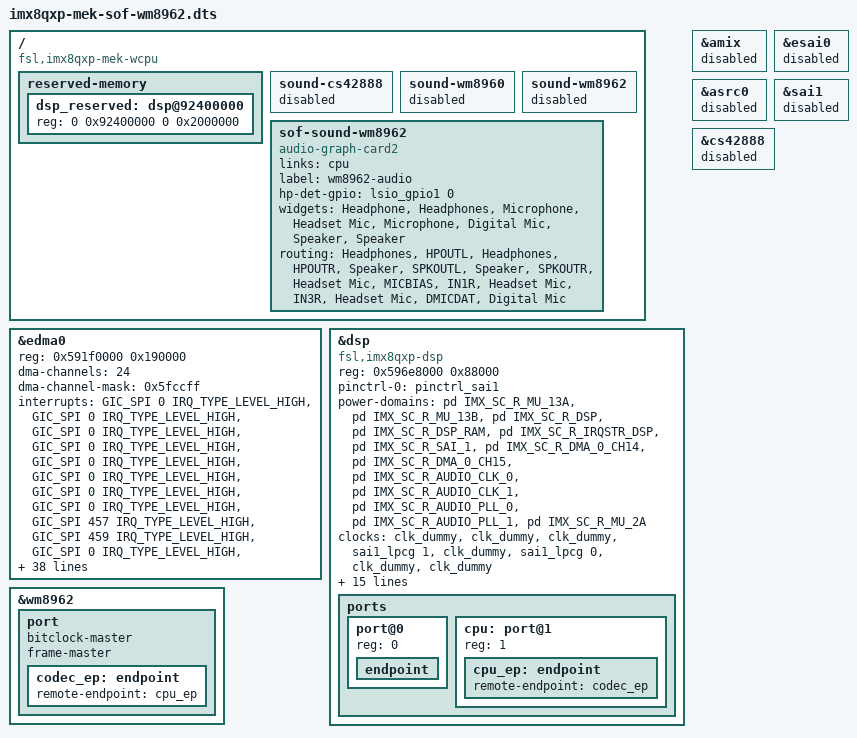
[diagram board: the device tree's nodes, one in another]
// SPDX-License-Identifier: GPL-2.0+
/*
 * Copyright 2023 NXP
 */

#include "imx8qxp-mek-rpmsg.dts"

/delete-node/ &dsp_reserved_heap;
/delete-node/ &dsp_vdev0vring0;
/delete-node/ &dsp_vdev0vring1;
/delete-node/ &dsp_vdev0buffer;

/ {
	compatible = "fsl,imx8qxp-mek-wcpu";

	/delete-node/ sound-wm8960;
	/delete-node/ sound-wm8962;

	reserved-memory {
		dsp_reserved: dsp@92400000 {
			reg = <0 0x92400000 0 0x2000000>;
		};
	};

	sound-cs42888 {
		status = "disabled";
	};

	sound-wm8960 {
		status = "disabled";
	};

	sound-wm8962 {
		status = "disabled";
	};

	sof-sound-wm8962 {
		compatible = "audio-graph-card2";
		links = <&cpu>;
		label = "wm8962-audio";
		hp-det-gpio = <&lsio_gpio1 0 0>;
		widgets =
			"Headphone", "Headphones",
			"Microphone", "Headset Mic",
			"Microphone", "Digital Mic",
			"Speaker", "Speaker";
		routing =
			"Headphones", "HPOUTL",
			"Headphones", "HPOUTR",
			"Speaker", "SPKOUTL",
			"Speaker", "SPKOUTR",
			"Headset Mic", "MICBIAS",
			"IN1R", "Headset Mic",
			"IN3R", "Headset Mic",
			"DMICDAT", "Digital Mic";
	};
};

&edma0 {
	reg = <0x591f0000 0x190000>;
	dma-channels = <24>;
	dma-channel-mask = <0x5fccff>;
	interrupts = <GIC_SPI 0   IRQ_TYPE_LEVEL_HIGH>, /* 0 asrc 0 */
		     <GIC_SPI 0   IRQ_TYPE_LEVEL_HIGH>, /* 1 */
		     <GIC_SPI 0   IRQ_TYPE_LEVEL_HIGH>, /* 2 */
		     <GIC_SPI 0   IRQ_TYPE_LEVEL_HIGH>, /* 3 */
		     <GIC_SPI 0   IRQ_TYPE_LEVEL_HIGH>, /* 4 */
		     <GIC_SPI 0   IRQ_TYPE_LEVEL_HIGH>, /* 5 */
		     <GIC_SPI 0   IRQ_TYPE_LEVEL_HIGH>, /* 6 esai0 */
		     <GIC_SPI 0   IRQ_TYPE_LEVEL_HIGH>, /* 7 */
		     <GIC_SPI 457 IRQ_TYPE_LEVEL_HIGH>, /* 8 spdif0 */
		     <GIC_SPI 459 IRQ_TYPE_LEVEL_HIGH>, /* 9 */
		     <GIC_SPI 0   IRQ_TYPE_LEVEL_HIGH>, /* 10 unused */
		     <GIC_SPI 0   IRQ_TYPE_LEVEL_HIGH>, /* 11 unused */
		     <GIC_SPI 315 IRQ_TYPE_LEVEL_HIGH>, /* 12 sai0 */
		     <GIC_SPI 315 IRQ_TYPE_LEVEL_HIGH>, /* 13 */
		     <GIC_SPI 0   IRQ_TYPE_LEVEL_HIGH>, /* 14 sai1 */
		     <GIC_SPI 0   IRQ_TYPE_LEVEL_HIGH>, /* 15 */
		     <GIC_SPI 0   IRQ_TYPE_LEVEL_HIGH>, /* 16 sai2 */
		     <GIC_SPI 0   IRQ_TYPE_LEVEL_HIGH>, /* 17 sai3 */
		     <GIC_SPI 0   IRQ_TYPE_LEVEL_HIGH>, /* 18 unused */
		     <GIC_SPI 0   IRQ_TYPE_LEVEL_HIGH>, /* 19 unused */
		     <GIC_SPI 0   IRQ_TYPE_LEVEL_HIGH>, /* 20 unused */
		     <GIC_SPI 391 IRQ_TYPE_LEVEL_HIGH>, /* 21 */
		     <GIC_SPI 0   IRQ_TYPE_LEVEL_HIGH>, /* 22 unused */
		     <GIC_SPI 393 IRQ_TYPE_LEVEL_HIGH>, /* 23 */
		     <GIC_SPI 369 IRQ_TYPE_LEVEL_HIGH>;
	power-domains = <&pd IMX_SC_R_DMA_0_CH0>,
			<&pd IMX_SC_R_DMA_0_CH1>,
			<&pd IMX_SC_R_DMA_0_CH2>,
			<&pd IMX_SC_R_DMA_0_CH3>,
			<&pd IMX_SC_R_DMA_0_CH4>,
			<&pd IMX_SC_R_DMA_0_CH5>,
			<&pd IMX_SC_R_DMA_0_CH6>,
			<&pd IMX_SC_R_DMA_0_CH7>,
			<&pd IMX_SC_R_DMA_0_CH8>,
			<&pd IMX_SC_R_DMA_0_CH9>,
			<&pd IMX_SC_R_DMA_0_CH10>,
			<&pd IMX_SC_R_DMA_0_CH11>,
			<&pd IMX_SC_R_DMA_0_CH12>,
			<&pd IMX_SC_R_DMA_0_CH13>,
			<&pd IMX_SC_R_DMA_0_CH14>,
			<&pd IMX_SC_R_DMA_0_CH15>,
			<&pd IMX_SC_R_DMA_0_CH16>,
			<&pd IMX_SC_R_DMA_0_CH17>,
			<&pd IMX_SC_R_DMA_0_CH18>,
			<&pd IMX_SC_R_DMA_0_CH19>,
			<&pd IMX_SC_R_DMA_0_CH20>,
			<&pd IMX_SC_R_DMA_0_CH21>,
			<&pd IMX_SC_R_DMA_0_CH22>,
			<&pd IMX_SC_R_DMA_0_CH23>;
};

&dsp {
	compatible = "fsl,imx8qxp-dsp";
	reg = <0x596e8000 0x88000>;

	pinctrl-names = "default";
	pinctrl-0 = <&pinctrl_sai1>;

	power-domains = <&pd IMX_SC_R_MU_13A>,
		<&pd IMX_SC_R_MU_13B>,
		<&pd IMX_SC_R_DSP>,
		<&pd IMX_SC_R_DSP_RAM>,
		<&pd IMX_SC_R_IRQSTR_DSP>,
		<&pd IMX_SC_R_SAI_1>,
		<&pd IMX_SC_R_DMA_0_CH14>,
		<&pd IMX_SC_R_DMA_0_CH15>,
		<&pd IMX_SC_R_AUDIO_CLK_0>,
		<&pd IMX_SC_R_AUDIO_CLK_1>,
		<&pd IMX_SC_R_AUDIO_PLL_0>,
		<&pd IMX_SC_R_AUDIO_PLL_1>,
		<&pd IMX_SC_R_MU_2A>;

	clock-names = "ipg", "ocram", "core",
		"sai1_bus", "sai1_mclk0", "sai1_mclk1", "sai1_mclk2", "sai1_mclk3";
	clocks = <&clk_dummy>, <&clk_dummy>, <&clk_dummy>,
		<&sai1_lpcg 1>, <&clk_dummy>, <&sai1_lpcg 0>,
		<&clk_dummy>, <&clk_dummy>;
	assigned-clocks = <&acm IMX_ADMA_ACM_SAI1_MCLK_SEL>,
			<&clk IMX_SC_R_AUDIO_PLL_0 IMX_SC_PM_CLK_PLL>,
			<&clk IMX_SC_R_AUDIO_PLL_0 IMX_SC_PM_CLK_MISC0>,
			<&clk IMX_SC_R_AUDIO_PLL_0 IMX_SC_PM_CLK_MISC1>,
			<&sai1_lpcg 0>; /* FIXME: should be sai1, original code is 0 */
	assigned-clock-parents = <&aud_pll_div0_lpcg 0>;
	assigned-clock-rates = <0>, <786432000>, <49152000>, <12288000>, <49152000>;

	mbox-names = "txdb0", "txdb1", "rxdb0", "rxdb1";
	mboxes = <&lsio_mu13 2 0>,
		<&lsio_mu13 2 1>,
		<&lsio_mu13 3 0>,
		<&lsio_mu13 3 1>;
	memory-region = <&dsp_reserved>;
	/delete-property/ firmware-name;

	tplg-name = "sof-imx8-wm8962.tplg";
	machine-drv-name = "asoc-audio-graph-card2";
	status = "okay";

	ports {
		#address-cells = <1>;
		#size-cells = <0>;

		port@0 { reg = <0>; endpoint { /* not used */ }; };
		cpu: port@1 { reg = <1>; cpu_ep: endpoint { remote-endpoint = <&codec_ep>; }; };
	};
};

&wm8962 {
	status = "okay";
	port {
		bitclock-master;
		frame-master;
		codec_ep: endpoint { remote-endpoint = <&cpu_ep>; };
	};
};

&amix {
	status = "disabled";
};

&esai0 {
	status = "disabled";
};

&asrc0 {
	status = "disabled";
};

&sai1 {
	status = "disabled";
};

&cs42888 {
	status = "disabled";
};
